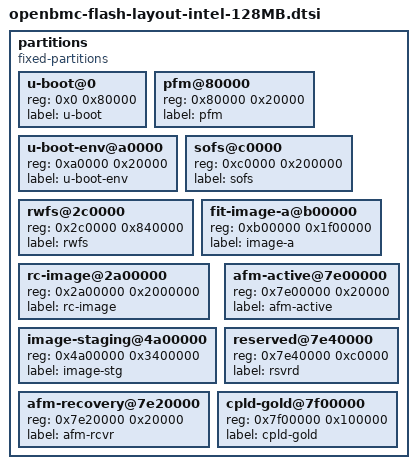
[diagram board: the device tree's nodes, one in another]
// SPDX-License-Identifier: GPL-2.0+
// 128MB flash layout: PFR (active + tmp1/tmp2 + extra)
//                     image with common RW partition

partitions {
	compatible = "fixed-partitions";
	#address-cells = <1>;
	#size-cells = <1>;

	u-boot@0 {
		reg = <0x0 0x80000>;
		label = "u-boot";
	};

	pfm@80000 {
		reg = <0x80000 0x20000>;
		label = "pfm";
	};

	u-boot-env@a0000 {
		reg = <0xa0000 0x20000>;
		label = "u-boot-env";
	};

	sofs@c0000 {
		reg = <0xc0000 0x200000>;
		label = "sofs";
	};

	rwfs@2c0000 {
		reg = <0x2c0000 0x840000>;
		label = "rwfs";
	};

	fit-image-a@b00000 {
		reg = <0xb00000 0x1f00000>;
		label = "image-a";
	};

	rc-image@2a00000 {
		reg = <0x2a00000 0x2000000>;
		label = "rc-image";
	};

	image-staging@4a00000 {
		reg = <0x4a00000 0x3400000>;
		label = "image-stg";
	};

	afm-active@7e00000 {
		reg = <0x7e00000 0x20000>;
		label = "afm-active";
	};

	afm-recovery@7e20000 {
		reg = <0x7e20000 0x20000>;
		label = "afm-rcvr";
	};

	reserved@7e40000 {
		reg = <0x7e40000 0xc0000>;
		label = "rsvrd";
	};

	cpld-gold@7f00000 {
		reg = <0x7f00000 0x100000>;
		label = "cpld-gold";
	};
};
